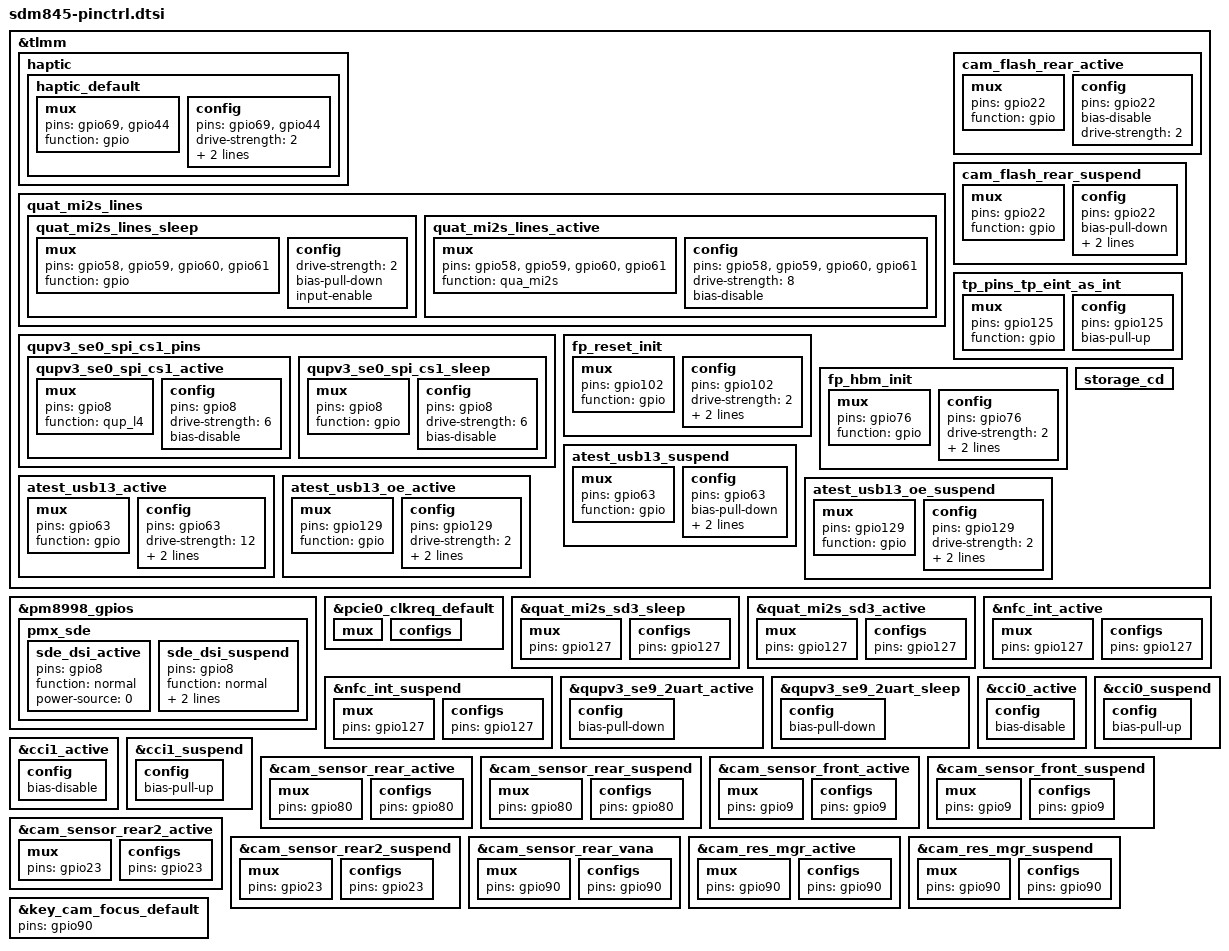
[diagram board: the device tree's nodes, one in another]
/*
 * Copyright (C) 2023 transaero21 <transaero21@elseboot.ru>
 *
 * SPDX-License-Identifier: GPL-2.0
 */

&tlmm {
	/delete-node/ spkr_i2s_clk_pin;
	/delete-node/ pmx_sde;

	haptic {
		haptic_default: haptic_default {
			mux {
				pins = "gpio69", "gpio44";
				function = "gpio";
			};

			config {
				pins = "gpio69", "gpio44";
				drive-strength = <2>;
				bias-pull-up;
				input-enable;
			};
		};
	};

	quat_mi2s_lines {
		quat_mi2s_lines_sleep: quat_mi2s_lines_sleep {
			mux {
				pins = "gpio58", "gpio59", "gpio60", "gpio61";
				function = "gpio";
			};

			config {
				drive-strength = <2>;
				bias-pull-down;
				input-enable;
			};
		};

		quat_mi2s_lines_active: quat_mi2s_lines_active {
			mux {
				pins = "gpio58", "gpio59", "gpio60", "gpio61";
				function = "qua_mi2s";
			};

			config {
				pins = "gpio58", "gpio59", "gpio60", "gpio61";
				drive-strength = <8>;
				bias-disable;
			};
		};
	};

	qupv3_se0_spi_cs1_pins: qupv3_se0_spi_cs1_pins {
		qupv3_se0_spi_cs1_active: qupv3_se0_spi_cs1_active {
			mux {
				pins = "gpio8";
				function = "qup_l4";
			};

			config {
				pins = "gpio8";
				drive-strength = <6>;
				bias-disable;
			};
		};

		qupv3_se0_spi_cs1_sleep: qupv3_se0_spi_cs1_sleep {
			mux {
				pins = "gpio8";
				function = "gpio";
			};

			config {
				pins = "gpio8";
				drive-strength = <6>;
				bias-disable;
			};
		};
	};

	cam_flash_rear_active: cam_flash_rear_active {
		/* RESET,AVDD LO ,IMG_START, ILLU_EN */
		mux {
			pins = "gpio22";
			function = "gpio";
		};

		config {
			pins = "gpio22";
			bias-disable; /* No PULL */
			drive-strength = <2>; /* 2 MA */
		};
	};

	cam_flash_rear_suspend: cam_flash_rear_suspend {
		/* RESET, AVDD LO ,IMG_START, ILLU_EN */
		mux {
			pins = "gpio22";
			function = "gpio";
		};

		config {
			pins = "gpio22";
			bias-pull-down; /* PULL DOWN */
			drive-strength = <2>; /* 2 MA */
			output-low;
		};
	};

	tp_pins_tp_eint_as_int: tp_pins_tp_eint_as_int {
		mux {
			pins = "gpio125";
			function = "gpio";
		};

		config {
			pins = "gpio125";
			bias-pull-up;
		};
	};

	fp_reset_init: fp_reset_init {
		mux {
			pins = "gpio102";
			function = "gpio";
		};

		config {
			pins = "gpio102";
			drive-strength = <2>;
			bias-disable;
			output-low;
		};
	};

	fp_hbm_init: fp_hbm_init {
		mux {
			pins = "gpio76";
			function = "gpio";
   		};

		config {
			pins = "gpio76";
			drive-strength = <2>;
			bias-disable;
			output-low;
		};
	};

	atest_usb13_active: atest_usb13_active {
		mux {
			pins = "gpio63";
			function = "gpio";
		};

		config {
			pins = "gpio63";
			drive-strength = <12>;
			bias-pull-up;
			output-high;
		};
	};

	atest_usb13_suspend: atest_usb13_suspend {
		mux {
			pins = "gpio63";
			function = "gpio";
		};

		config {
			pins = "gpio63";
			bias-pull-down;
			drive-strength = <2>;
			output-low;
		};
	};

	atest_usb13_oe_active: atest_usb13_oe_active {
		mux {
			pins = "gpio129";
			function = "gpio";
		};

		config {
			pins = "gpio129";
			drive-strength = <2>;
			bias-pull-down;
			output-low;
		};
	};

	atest_usb13_oe_suspend: atest_usb13_oe_suspend {
		mux {
			pins = "gpio129";
			function = "gpio";
		};

		config {
			pins = "gpio129";
			drive-strength = <2>;
			bias-pull-up;
			output-high;
		};
	};

	/* DO NOT REMOVE */
	storage_cd: storage_cd {};
};

&pm8998_gpios {
	pmx_sde: pmx_sde {
		sde_dsi_active: sde_dsi_active {
			pins = "gpio8";
			function = "normal";
			power-source = <0>;
		};

		sde_dsi_suspend: sde_dsi_suspend {
			pins = "gpio8";
			function = "normal";
			power-source = <0>;
			bias-pull-down;
		};
	};
};

&pcie0_clkreq_default {
	mux {
		/delete-property/ pins;
		/delete-property/ function;
	};

	configs {
		/delete-property/ pins;
		/delete-property/ drive-strength;
		/delete-property/ bias-pull-up;
	};
};

&quat_mi2s_sd3_sleep {
	mux {
		pins = "gpio127";
	};

	configs {
		pins = "gpio127";
	};
};

&quat_mi2s_sd3_active {
	mux {
		pins = "gpio127";
	};

	configs {
		pins = "gpio127";
	};
};

&nfc_int_active {
	mux {
		pins = "gpio127";
	};

	configs {
		pins = "gpio127";
	};
};

&nfc_int_suspend {
	mux {
		pins = "gpio127";
	};

	configs {
		pins = "gpio127";
	};
};

&qupv3_se9_2uart_active {
	config {
		/delete-property/ bias-disable;
		bias-pull-down;
	};
};

&qupv3_se9_2uart_sleep {
	config {
		/delete-property/ bias-disable;
		bias-pull-down;
	};
};

&cci0_active {
	config {
		/delete-property/ bias-pull-up;
		bias-disable;
	};
};

&cci0_suspend {
	config {
		/delete-property/ bias-pull-down;
		bias-pull-up;
	};
};

&cci1_active {
	config {
		/delete-property/ bias-pull-up;
		bias-disable;
	};
};

&cci1_suspend {
	config {
		/delete-property/ bias-pull-down;
		bias-pull-up;
	};
};

&cam_sensor_rear_active {
	mux {
		pins = "gpio80";
	};

	configs {
		pins = "gpio80";
	};
};

&cam_sensor_rear_suspend {
	mux {
		pins = "gpio80";
	};

	configs {
		pins = "gpio80";
	};
};

&cam_sensor_front_active {
	mux {
		pins = "gpio9";
	};

	configs {
		pins = "gpio9";
	};
};

&cam_sensor_front_suspend {
	mux {
		pins = "gpio9";
	};

	configs {
		pins = "gpio9";
	};
};

&cam_sensor_rear2_active {
	mux {
		pins = "gpio23";
	};

	configs {
		pins = "gpio23";
	};
};

&cam_sensor_rear2_suspend {
	mux {
		pins = "gpio23";
	};

	configs {
		pins = "gpio23";
	};
};

&cam_sensor_rear_vana {
	mux {
		pins = "gpio90";
	};

	configs {
		pins = "gpio90";
	};
};

&cam_res_mgr_active {
	mux {
		pins = "gpio90";
	};

	configs {
		pins = "gpio90";
	};
};

&cam_res_mgr_suspend {
	mux {
		pins = "gpio90";
	};

	configs {
		pins = "gpio90";
	};
};

&key_cam_focus_default {
	pins = "gpio90";
};
